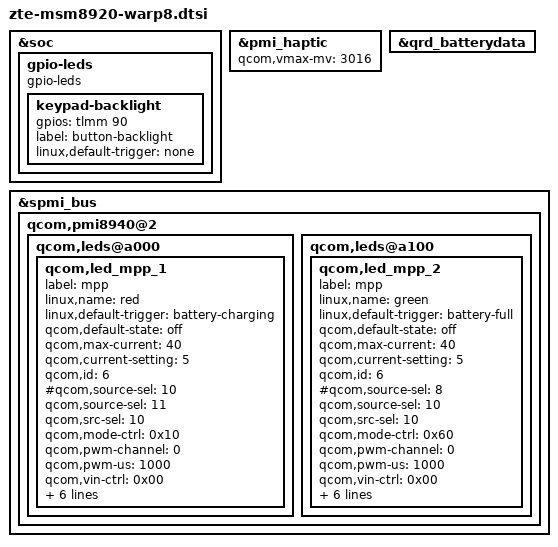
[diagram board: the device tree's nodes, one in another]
/*
 * device tree for zte warp8 board
 */
#include "touch-key-backlight-warp8.dtsi"


&soc {
	gpio-leds {
		compatible = "gpio-leds";
		keypad-backlight {
			gpios = <&tlmm 90 0>;
			label = "button-backlight";
			linux,default-trigger = "none";
		};
	};
};

&pmi_haptic {
	qcom,vmax-mv = <3016>;
};

&qrd_batterydata {
	#include "zte_p817a22_3250mah.dtsi"
};

&spmi_bus {
	qcom,pmi8940@2 {
		qcom,leds@a000 {
			status = "okay";
			qcom,led_mpp_1 {	/* red led */
				label = "mpp";
				linux,name = "red";		/* orgin is wled-backlight */
				linux,default-trigger = "battery-charging";	/* org="bkl-trigger"; */
				qcom,default-state = "off";
				qcom,max-current = <40>;
				qcom,current-setting = <5>;	/*+ zte add +*/
				qcom,id = <6>;				/* in leds-qpnp.c enum QPNP_ID_LED_MPP(6) */
				#qcom,source-sel = <10>;	/* select power source, default 1 (enabled)(org=8) */
				qcom,source-sel = <11>; /* connect MPP to inverted DTEST2 for PMI8940 */
				qcom,src-sel = <10>;
				qcom,mode-ctrl = <0x10>;	/* operation mode, default 0x60 = Mode Sink (org=0x10)*/
				qcom,pwm-channel = <0>;
				qcom,pwm-us = <1000>;
				qcom,vin-ctrl = <0x00>;		/* select input source, 0 to 3 */
				qcom,duty-pcts = <50>;
				qcom,mode = "pwm";
				qcom,use-blink;
				pwms = <&pmi8940_pwm 0 0>;
				qcom,pwm-names = "red-led";
				zte,is-operator-sprint = "no";
			};
		};

		qcom,leds@a100 {
			status = "okay";
			qcom,led_mpp_2 {	/* green led */
				label = "mpp";
				linux,name = "green";
				linux,default-trigger = "battery-full";
				qcom,default-state = "off";
				qcom,max-current = <40>;
				qcom,current-setting = <5>;
				qcom,id = <6>;
				#qcom,source-sel = <8>;
				qcom,source-sel = <10>; /* connect MPP to DTEST2*/
				qcom,src-sel = <10>;

				qcom,mode-ctrl = <0x60>;
				qcom,pwm-channel = <0>;
				qcom,pwm-us = <1000>;
				qcom,vin-ctrl = <0x00>;
				qcom,duty-pcts = <50>;
				qcom,mode = "pwm";
				qcom,use-blink;
				pwms = <&pmi8940_pwm 0 0>;
				qcom,pwm-names = "green-led";
				zte,is-operator-sprint = "no";
			};
		};
	};
};
